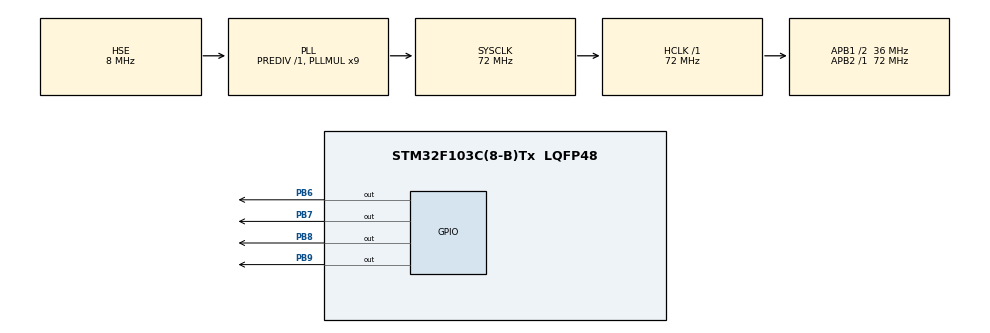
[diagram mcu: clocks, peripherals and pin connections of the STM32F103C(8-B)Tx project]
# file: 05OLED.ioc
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Mcu.Family=STM32F1
Mcu.Name=STM32F103C(8-B)Tx
Mcu.Package=LQFP48
NVIC.PriorityGroup=NVIC_PRIORITYGROUP_4
PA13.Mode=Serial_Wire
PA13.Signal=SYS_JTMS-SWDIO
PA14.Mode=Serial_Wire
PA14.Signal=SYS_JTCK-SWCLK
PB6.Signal=GPIO_Output
PB7.PinState=GPIO_PIN_SET
PB7.Signal=GPIO_Output
PB8.GPIO_ModeDefaultOutputPP=GPIO_MODE_OUTPUT_OD
PB8.GPIO_PuPd=GPIO_PULLUP
PB8.PinState=GPIO_PIN_SET
PB8.Signal=GPIO_Output
PB9.GPIO_ModeDefaultOutputPP=GPIO_MODE_OUTPUT_OD
PB9.GPIO_PuPd=GPIO_PULLUP
PB9.PinState=GPIO_PIN_SET
PB9.Signal=GPIO_Output
PD0-OSC_IN.Mode=HSE-External-Oscillator
PD0-OSC_IN.Signal=RCC_OSC_IN
PD1-OSC_OUT.Mode=HSE-External-Oscillator
PD1-OSC_OUT.Signal=RCC_OSC_OUT
ProjectManager.HeapSize=0x200
ProjectManager.StackSize=0x400
ProjectManager.TargetToolchain=MDK-ARM V5.32
RCC.AHBFreq_Value=72000000
RCC.APB1CLKDivider=RCC_HCLK_DIV2
RCC.APB1Freq_Value=36000000
RCC.APB1TimFreq_Value=72000000
RCC.APB2Freq_Value=72000000
RCC.APB2TimFreq_Value=72000000
RCC.HCLKFreq_Value=72000000
RCC.PLLMUL=RCC_PLL_MUL9
RCC.PLLSourceVirtual=RCC_PLLSOURCE_HSE
RCC.SYSCLKFreq_VALUE=72000000
RCC.SYSCLKSource=RCC_SYSCLKSOURCE_PLLCLK
RCC.USBFreq_Value=72000000
board=custom

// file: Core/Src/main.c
/* USER CODE BEGIN Header */
/**
  ******************************************************************************
  * @file           : main.c
  * @brief          : Main program body
  ******************************************************************************
  * @attention
  *
  * Copyright (c) 2025 STMicroelectronics.
  * All rights reserved.
  *
  * This software is licensed under terms that can be found in the LICENSE file
  * in the root directory of this software component.
  * If no LICENSE file comes with this software, it is provided AS-IS.
  *
  ******************************************************************************
  */
/* USER CODE END Header */
#include "main.h"
#include "gpio.h"

/* USER CODE BEGIN Includes */
// 添加OLED头文件
#include "OLED.h"

/* USER CODE END Includes */

/* USER CODE BEGIN PTD */
	char arr[] = {'B'};
	char arr1[] = "Hello World!"; // 自动添加\0

/* USER CODE END PTD */

void SystemClock_Config(void);

int main(void)
{

  /* MCU Configuration--------------------------------------------------------*/

  /* Reset of all peripherals, Initializes the Flash interface and the Systick. */
  HAL_Init();

  /* Configure the system clock */
  SystemClock_Config();

  /* Initialize all configured peripherals */
  MX_GPIO_Init();
  /* USER CODE BEGIN 2 */
  	OLED_Init(); // 初始化OLED显示屏
	OLED_Clear();
	// 在第一行 第一列显示字符'A'
	OLED_ShowChar(1, 1, 'A'); // 在指定位置显示单个字符

	// 在第一行 第二列显示字符'B'
	OLED_ShowChar(1, 2, arr[0]);

	// 在第一行 第三列显示字符串HELLOWORD
	OLED_ShowString(1, 3, arr1); // 在指定位置显示字符串

	// 在第二行 第一列显示数字12345 长度为5
	OLED_ShowNum(2, 1, 12345, 5); // 显示十进制正整数

	// 在第二行 第七列显示数字12345 长度为5(前面会带+号)
	OLED_ShowSignedNum(2, 7, 12345, 5); // 显示带符号的十进制数

	// 在第三行 第一列显示数字-66 长度为2(前面会带-号)
	OLED_ShowSignedNum(3, 1, -66, 2); // 显示带符号的十进制数

	// 在第四行 第一列显示十六进制数字0XAA55 长度为4(前面会带-号)
	OLED_ShowHexNum(4, 1, 0XAA55, 4);   // 显示十六进制数

	// 在第四行 第七列显示二进制数字0XFF(二进制用十六进制代替) 长度为8 若为9 则前面会补0
	OLED_ShowBinNum(4, 7, 0XFF, 8); // 显示二进制数

  /* USER CODE END 2 */

  /* Infinite loop */
  while (1)
  {

  }
}

void SystemClock_Config(void)
{
  RCC_OscInitTypeDef RCC_OscInitStruct = {0};
  RCC_ClkInitTypeDef RCC_ClkInitStruct = {0};

  /** Initializes the RCC Oscillators according to the specified parameters
  * in the RCC_OscInitTypeDef structure.
  */
  RCC_OscInitStruct.OscillatorType = RCC_OSCILLATORTYPE_HSE;
  RCC_OscInitStruct.HSEState = RCC_HSE_ON;
  RCC_OscInitStruct.HSEPredivValue = RCC_HSE_PREDIV_DIV1;
  RCC_OscInitStruct.HSIState = RCC_HSI_ON;
  RCC_OscInitStruct.PLL.PLLState = RCC_PLL_ON;
  RCC_OscInitStruct.PLL.PLLSource = RCC_PLLSOURCE_HSE;
  RCC_OscInitStruct.PLL.PLLMUL = RCC_PLL_MUL9;
  if (HAL_RCC_OscConfig(&RCC_OscInitStruct) != HAL_OK)
  {
    Error_Handler();
  }

  /** Initializes the CPU, AHB and APB buses clocks
  */
  RCC_ClkInitStruct.ClockType = RCC_CLOCKTYPE_HCLK|RCC_CLOCKTYPE_SYSCLK
                              |RCC_CLOCKTYPE_PCLK1|RCC_CLOCKTYPE_PCLK2;
  RCC_ClkInitStruct.SYSCLKSource = RCC_SYSCLKSOURCE_PLLCLK;
  RCC_ClkInitStruct.AHBCLKDivider = RCC_SYSCLK_DIV1;
  RCC_ClkInitStruct.APB1CLKDivider = RCC_HCLK_DIV2;
  RCC_ClkInitStruct.APB2CLKDivider = RCC_HCLK_DIV1;

  if (HAL_RCC_ClockConfig(&RCC_ClkInitStruct, FLASH_LATENCY_2) != HAL_OK)
  {
    Error_Handler();
  }
}

void Error_Handler(void)
{
  __disable_irq();
  while (1)
  {
  }
}
